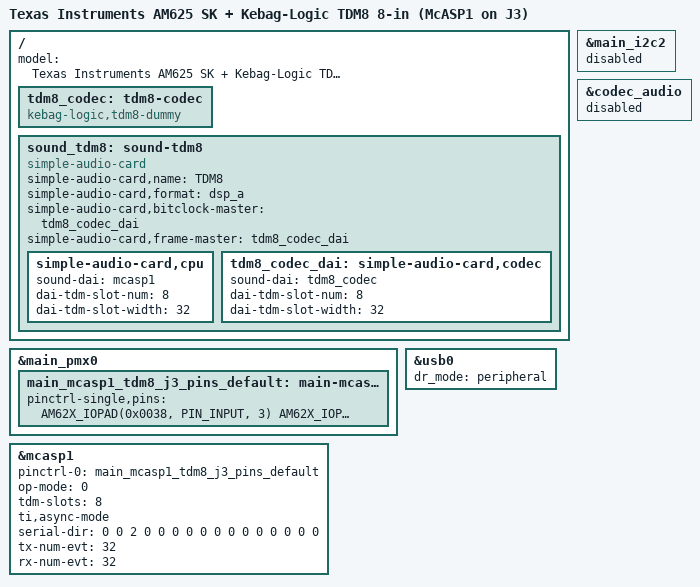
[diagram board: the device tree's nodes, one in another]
// SPDX-License-Identifier: GPL-2.0-only OR MIT
/*
 * TDM8 capture (8 in) on McASP1, taken off the SK-AM62B-P1 40-pin user
 * expansion header J3, bridged to the USB Audio Class 2.0 gadget.
 *
 * SPDX-FileCopyrightText: Copyright (c) 2026 Kebag-Logic
 *
 * THIS VARIANT IS CAPTURE ONLY - 8 slots FPGA -> board, nothing back, for the
 * same reason as k3-am625-sk-tdm8-j3.dts: a McASP transmit section is always
 * clocked from its own ACLKX/AFSX pins, and per the AM625 datasheet
 * (SPRSP58C tables 5-35..5-37) the ALW balls that can carry a transmit frame
 * sync are
 *
 *   MCASP0_AFSX  D20
 *   MCASP1_AFSX  B23, J22, U23
 *   MCASP2_AFSX  A15, AD21, T22
 *
 * and not one of those seven is on J3, J9, J10 or J15.  Full duplex on this
 * board needs the McASP1 audio bus - see k3-am625-sk-tdm8.dts.
 *
 * Why this exists next to k3-am625-sk-tdm8-j3.dts: the McASP0 variant has to
 * borrow J3-39 and J3-12, which are MAIN_UART1 TXD/RXD - the port mainline
 * marks status = "reserved" for the TIFS firmware trace.  McASP1's receive set
 * avoids that entirely:
 *
 *   J3-22  OSPI0_CSn3      pad 0x038 mux3  MCASP1_ACLKR  <- FPGA BCLK  12.288 MHz
 *   J3-5   GPMC0_CSn2      pad 0x0b0 mux8  MCASP1_AFSR   <- FPGA FSYNC 48 kHz
 *   J3-15  GPMC0_ADVn_ALE  pad 0x084 mux2  MCASP1_AXR2   <- FPGA DOUT  (8 slots in)
 *   J3-6/9/14/20/25/30/34  GND
 *
 * The cost is J3-5, which is SoC_I2C2_SCL on this board, so main_i2c2 is
 * disabled below.  J3-22 is free: the SK's ospi0 group claims CLK, CSn0, D0-D7
 * and DQS but not CSn3.  MCASP1_ACLKR is also on J3-3 (pad 0x0b4 mux8), which
 * would cost I2C2_SDA as well - J3-22 is the cheaper pin.
 */

#include "k3-am625-sk.dts"

/ {
	model = "Texas Instruments AM625 SK + Kebag-Logic TDM8 8-in (McASP1 on J3)";

	tdm8_codec: tdm8-codec {
		compatible = "kebag-logic,tdm8-dummy";
		#sound-dai-cells = <0>;
		status = "okay";
	};

	sound_tdm8: sound-tdm8 {
		compatible = "simple-audio-card";
		simple-audio-card,name = "TDM8";
		simple-audio-card,format = "dsp_a";
		/* the FPGA owns BCLK and FSYNC - see k3-am625-sk-tdm8.dts */
		simple-audio-card,bitclock-master = <&tdm8_codec_dai>;
		simple-audio-card,frame-master = <&tdm8_codec_dai>;

		simple-audio-card,cpu {
			sound-dai = <&mcasp1>;
			dai-tdm-slot-num = <8>;
			dai-tdm-slot-width = <32>;
		};

		tdm8_codec_dai: simple-audio-card,codec {
			sound-dai = <&tdm8_codec>;
			dai-tdm-slot-num = <8>;
			dai-tdm-slot-width = <32>;
		};
	};
};

&main_pmx0 {
	main_mcasp1_tdm8_j3_pins_default: main-mcasp1-tdm8-j3-default-pins {
		pinctrl-single,pins = <
			AM62X_IOPAD(0x0038, PIN_INPUT, 3) /* (E24) OSPI0_CSn3.MCASP1_ACLKR     in  J3-22 */
			AM62X_IOPAD(0x00b0, PIN_INPUT, 8) /* (K22) GPMC0_CSn2.MCASP1_AFSR      in  J3-5  */
			AM62X_IOPAD(0x0084, PIN_INPUT, 2) /* (L23) GPMC0_ADVn_ALE.MCASP1_AXR2  in  J3-15 */
		>;
	};
};

/* J3-5 is SoC_I2C2_SCL; MCASP1_AFSR needs that pad */
&main_i2c2 {
	status = "disabled";
};

/* mcasp1 belongs to exactly one card; the 2-channel on-board one steps aside */
&codec_audio {
	status = "disabled";
};

&mcasp1 {
	pinctrl-names = "default";
	pinctrl-0 = <&main_mcasp1_tdm8_j3_pins_default>;

	op-mode = <0>;			/* DAVINCI_MCASP_IIS_MODE (not DIT) */
	tdm-slots = <8>;

	/*
	 * ASYNC=1 puts the receive section on ACLKR/AFSR, which is the whole
	 * point of this variant: those two are on J3 and AFSX is not.
	 */
	ti,async-mode;

	/* 0 = inactive, 1 = TX, 2 = RX.  AXR2 receives the 8 input slots. */
	serial-dir = <
		0 0 2 0
		0 0 0 0
		0 0 0 0
		0 0 0 0
	>;
	tx-num-evt = <32>;
	rx-num-evt = <32>;
	status = "okay";
};

&usb0 {
	dr_mode = "peripheral";
};
